VERSION "HIPBNYYYYYYYYYYYYYYYYYYYYYYYYYYYYYYYYYYYYY/4/%%%/4/'%**4YYY///"

NS_ :

BS_:

BU_:

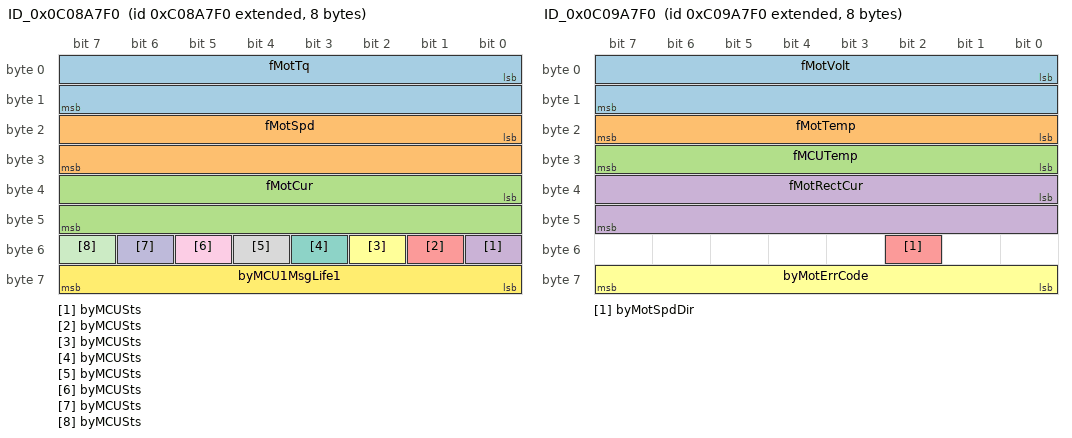
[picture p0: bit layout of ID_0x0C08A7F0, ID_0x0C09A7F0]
BO_ 2349377520 ID_0x0C08A7F0: 8 Vector__XXX
 SG_ fMotTq : 0|16@1+ (1,-32000) [-32000|33535] "NM" Vector__XXX
 SG_ fMotSpd : 16|16@1+ (0.5,0) [0|32767.5] "RPM" Vector__XXX
 SG_ fMotCur : 32|16@1+ (0.1,-1000) [-1000|5553.5] "A" Vector__XXX
 SG_ byMCUSts : 48|1@1+ (1,0) [0|1] "" Vector__XXX
 SG_ byMCUSts : 49|1@1+ (1,0) [0|1] "" Vector__XXX
 SG_ byMCUSts : 50|1@1+ (1,0) [0|1] "" Vector__XXX
 SG_ byMCUSts : 51|1@1+ (1,0) [0|1] "" Vector__XXX
 SG_ byMCUSts : 52|1@1+ (1,0) [0|1] "" Vector__XXX
 SG_ byMCUSts : 53|1@1+ (1,0) [0|1] "" Vector__XXX
 SG_ byMCUSts : 54|1@1+ (1,0) [0|1] "" Vector__XXX
 SG_ byMCUSts : 55|1@1+ (1,0) [0|1] "" Vector__XXX
 SG_ byMCU1MsgLife1 : 56|8@1+ (1,0) [0|255] "" Vector__XXX

BO_ 2349443056 ID_0x0C09A7F0: 8 Vector__XXX
 SG_ fMotVolt : 0|16@1+ (0.1,-1000) [-1000|5553.5] "V" Vector__XXX
 SG_ fMotTemp : 16|8@1+ (1,-40) [-40|215] "¡æ" Vector__XXX
 SG_ fMCUTemp : 24|8@1+ (1,-40) [-40|215] "¡æ" Vector__XXX
 SG_ fMotRectCur : 32|16@1+ (0.1,-1000) [-1000|5553.5] "A" Vector__XXX
 SG_ byMotSpdDir : 50|1@1+ (1,0) [0|1] "" Vector__XXX
 SG_ byMotErrCode : 56|8@1+ (1,0) [0|255] "" Vector__XXX

BO_ 2349508592 ID_0x0C0AA7F0: 8 Vector__XXX

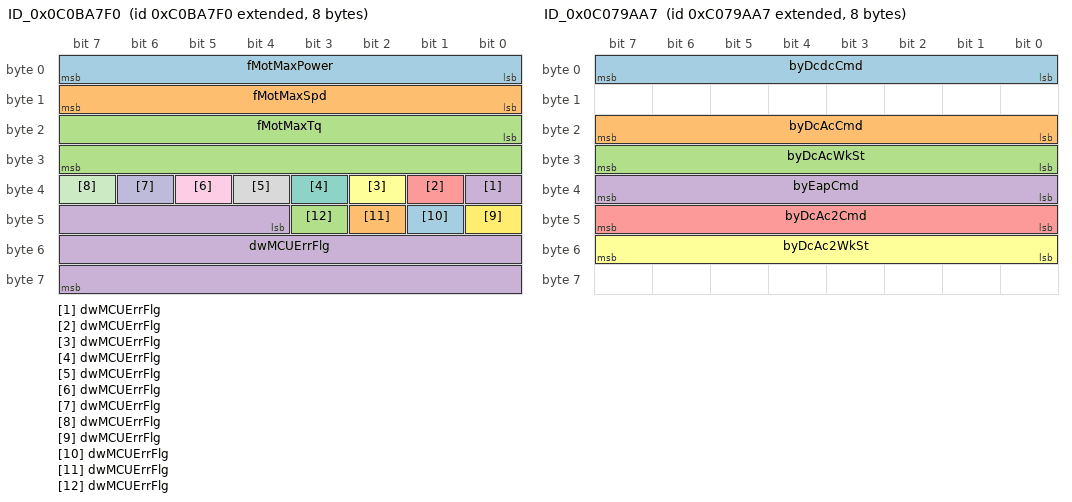
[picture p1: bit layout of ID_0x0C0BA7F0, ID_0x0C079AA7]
BO_ 2349574128 ID_0x0C0BA7F0: 8 Vector__XXX
 SG_ fMotMaxPower : 0|8@1+ (1,0) [0|255] "kw" Vector__XXX
 SG_ fMotMaxSpd : 8|8@1+ (100,0) [0|25500] "rpm" Vector__XXX
 SG_ fMotMaxTq : 16|16@1+ (1,0) [0|65535] "NM" Vector__XXX
 SG_ dwMCUErrFlg : 32|1@1+ (1,0) [0|1] "" Vector__XXX
 SG_ dwMCUErrFlg : 33|1@1+ (1,0) [0|1] "" Vector__XXX
 SG_ dwMCUErrFlg : 34|1@1+ (1,0) [0|1] "" Vector__XXX
 SG_ dwMCUErrFlg : 35|1@1+ (1,0) [0|1] "" Vector__XXX
 SG_ dwMCUErrFlg : 36|1@1+ (1,0) [0|1] "" Vector__XXX
 SG_ dwMCUErrFlg : 37|1@1+ (1,0) [0|1] "" Vector__XXX
 SG_ dwMCUErrFlg : 38|1@1+ (1,0) [0|1] "" Vector__XXX
 SG_ dwMCUErrFlg : 39|1@1+ (1,0) [0|1] "" Vector__XXX
 SG_ dwMCUErrFlg : 40|1@1+ (1,0) [0|1] "" Vector__XXX
 SG_ dwMCUErrFlg : 41|1@1+ (1,0) [0|1] "" Vector__XXX
 SG_ dwMCUErrFlg : 42|1@1+ (1,0) [0|1] "" Vector__XXX
 SG_ dwMCUErrFlg : 43|1@1+ (1,0) [0|1] "" Vector__XXX
 SG_ dwMCUErrFlg : 44|20@1+ (1,0) [0|1.04858e+006] "" Vector__XXX

BO_ 2349308583 ID_0x0C079AA7: 8 Vector__XXX
 SG_ byDcdcCmd : 0|8@1+ (1,0) [0|255] "" Vector__XXX
 SG_ byDcAcCmd : 16|8@1+ (1,0) [0|255] "" Vector__XXX
 SG_ byDcAcWkSt : 24|8@1+ (1,0) [0|255] "" Vector__XXX
 SG_ byEapCmd : 32|8@1+ (1,0) [0|255] "" Vector__XXX
 SG_ byDcAc2Cmd : 40|8@1+ (1,0) [0|255] "" Vector__XXX
 SG_ byDcAc2WkSt : 48|8@1+ (1,0) [0|255] "" Vector__XXX

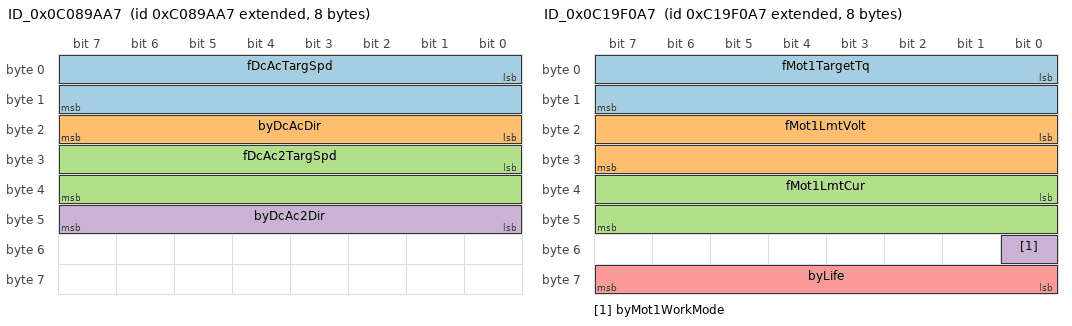
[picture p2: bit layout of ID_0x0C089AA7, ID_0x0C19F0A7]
BO_ 2349374119 ID_0x0C089AA7: 8 Vector__XXX
 SG_ fDcAcTargSpd : 0|16@1+ (1,0) [0|65535] "rpm" Vector__XXX
 SG_ byDcAcDir : 16|8@1+ (1,0) [0|255] "" Vector__XXX
 SG_ fDcAc2TargSpd : 24|16@1+ (1,0) [0|65535] "rpm" Vector__XXX
 SG_ byDcAc2Dir : 40|8@1+ (1,0) [0|255] "" Vector__XXX

BO_ 2349442971 ID_0x0C09A79B: 8 Vector__XXX

BO_ 2349508507 ID_0x0C0AA79B: 8 Vector__XXX

BO_ 2349508594 ID_0x0C0AA7F2: 8 Vector__XXX

BO_ 2350510247 ID_0x0C19F0A7: 8 Vector__XXX
 SG_ fMot1TargetTq : 0|16@1+ (1,0) [0|65535] "" Vector__XXX
 SG_ fMot1LmtVolt : 16|16@1+ (0.1,-1000) [-1000|5553.5] "V" Vector__XXX
 SG_ fMot1LmtCur : 32|16@1+ (0.1,-1000) [-1000|5553.5] "A" Vector__XXX
 SG_ byMot1WorkMode : 48|1@1+ (1,0) [0|1] "" Vector__XXX
 SG_ byLife : 56|8@1+ (1,0) [0|255] "" Vector__XXX

(*
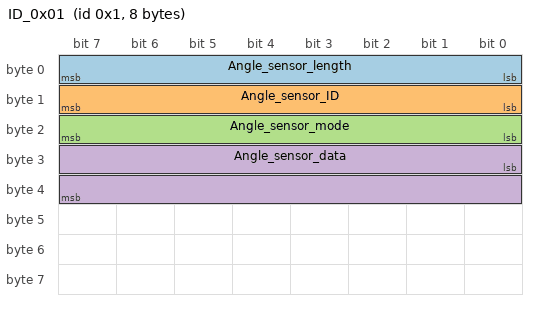
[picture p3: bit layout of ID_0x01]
BO_ 1 ID_0x01: 8 Vector__XXX
 SG_ Angle_sensor_front : 0|16@1+ (0.010986,0) [0|360] "deg" Vector__XXX

BO_ 2 ID_0x02: 8 Vector__XXX
 SG_ Angle_sensor_rear : 0|16@1+ (0.010986,0) [0|360] "deg" Vector__XXX
*)

BO_ 1 ID_0x01: 8 Vector__XXX
 SG_ Angle_sensor_length : 0|8@1+ (1,0) [0|8] "" Vector__XXX
 SG_ Angle_sensor_ID : 8|8@1+ (1,0) [0|8] "" Vector__XXX
 SG_ Angle_sensor_mode : 16|8@1+ (1,0) [0|8] "" Vector__XXX
 SG_ Angle_sensor_data : 24|16@1+ (0.010986,0) [0|360] "deg" Vector__XXX

BO_ 2333733032 ID_0x0B19F0A8: 8 Vector__XXX
 SG_ K1_High_low_Vol_control : 0|8@1+ (1,0) [0|10] "V" Vector__XXX
 SG_ K2_High_low_Vol_control : 8|8@1+ (1,0) [0|10] "V" Vector__XXX

CM_ SG_ 1 Angle_sensor_ID "Front 01,Rear 02";
CM_ SG_ 1 Angle_sensor_mode "Auto 04";
